AUTOSAR XML (schema 4-3-0)
package /ComponentTypes
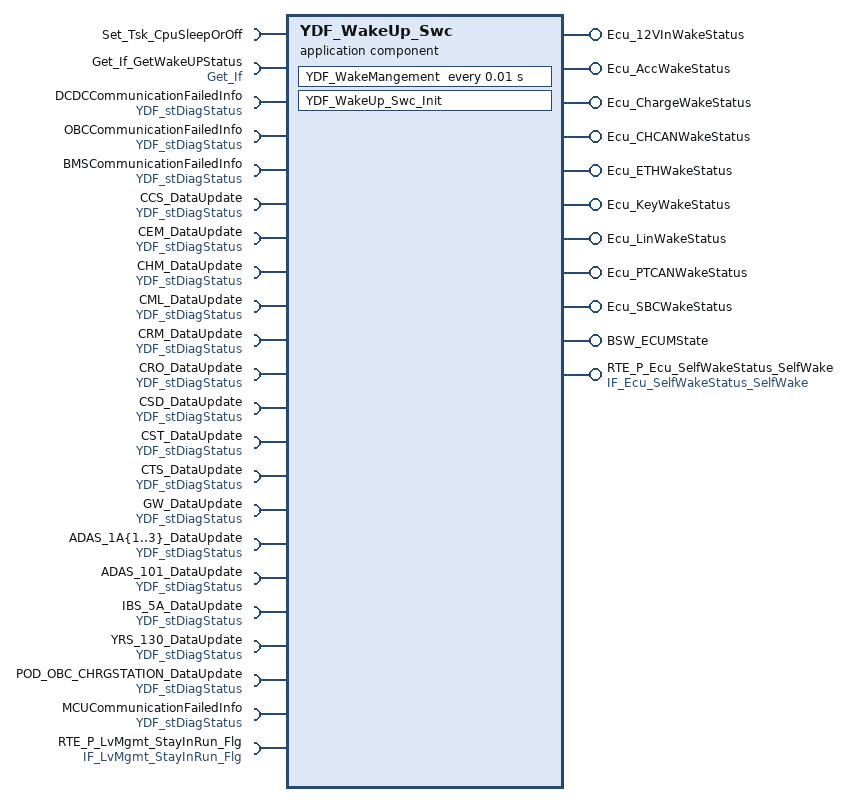
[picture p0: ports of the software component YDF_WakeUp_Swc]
  application sw component type YDF_WakeUp_Swc
    22 x require port:
      Set_Tsk_CpuSleepOrOff: client-com-spec=Set_Tsk_CpuSleepOrOff, required-interface=Set_Tsk_CpuSleepOrOff
      Get_If_GetWakeUPStatus: required-interface=Get_If
        required-com-specs:
          Get_Ad_Result
          Get_io_inResult
          Get_BTS_OutResult
          Get_CAN_ActiveInf
          Icu_17_GtmCcu6_PWMIN_CH{1..4}
          Icu_17_GtmCcu6_PWMIN_PWMSCB1
          Icu_17_GtmCcu6_PWMIN_PWMSCB2
          Icu_17_GtmCcu6_PWMIN_LAMPSCB1
          Icu_17_GtmCcu6_PWMIN_LAMPSCB2
          Get_Bottom_Ver
          Get_SentData
          Get_Level_OutResult
          Get_PwmOrLevel_OutResult
          Get_Motor_OutResult
      DCDCCommunicationFailedInfo: nonqueued-receiver-com-spec{data-element=DiagStatus, enable-update=true, filter=data-filter-type=ALWAYS, init-value=0}, required-interface=YDF_stDiagStatus
      OBCCommunicationFailedInfo: nonqueued-receiver-com-spec{data-element=DiagStatus, enable-update=true, filter=data-filter-type=ALWAYS, init-value=0}, required-interface=YDF_stDiagStatus
      BMSCommunicationFailedInfo: nonqueued-receiver-com-spec{data-element=DiagStatus, enable-update=true, filter=data-filter-type=ALWAYS, init-value=0}, required-interface=YDF_stDiagStatus
      CCS_DataUpdate: nonqueued-receiver-com-spec{data-element=DiagStatus, enable-update=true, filter=data-filter-type=ALWAYS, init-value=0}, required-interface=YDF_stDiagStatus
      CEM_DataUpdate: nonqueued-receiver-com-spec{data-element=DiagStatus, enable-update=true, filter=data-filter-type=ALWAYS, init-value=0}, required-interface=YDF_stDiagStatus
      CHM_DataUpdate: nonqueued-receiver-com-spec{data-element=DiagStatus, enable-update=true, filter=data-filter-type=ALWAYS, init-value=0}, required-interface=YDF_stDiagStatus
      CML_DataUpdate: nonqueued-receiver-com-spec{data-element=DiagStatus, enable-update=true, filter=data-filter-type=ALWAYS, init-value=0}, required-interface=YDF_stDiagStatus
      CRM_DataUpdate: nonqueued-receiver-com-spec{data-element=DiagStatus, enable-update=true, filter=data-filter-type=ALWAYS, init-value=0}, required-interface=YDF_stDiagStatus
      CRO_DataUpdate: nonqueued-receiver-com-spec{data-element=DiagStatus, enable-update=true, filter=data-filter-type=ALWAYS, init-value=0}, required-interface=YDF_stDiagStatus
      CSD_DataUpdate: nonqueued-receiver-com-spec{data-element=DiagStatus, enable-update=true, filter=data-filter-type=ALWAYS, init-value=0}, required-interface=YDF_stDiagStatus
      CST_DataUpdate: nonqueued-receiver-com-spec{data-element=DiagStatus, enable-update=true, filter=data-filter-type=ALWAYS, init-value=0}, required-interface=YDF_stDiagStatus
      CTS_DataUpdate: nonqueued-receiver-com-spec{data-element=DiagStatus, enable-update=true, filter=data-filter-type=ALWAYS, init-value=0}, required-interface=YDF_stDiagStatus
      GW_DataUpdate: nonqueued-receiver-com-spec{data-element=DiagStatus, enable-update=true, filter=data-filter-type=ALWAYS, init-value=0}, required-interface=YDF_stDiagStatus
      ADAS_1A{1..3}_DataUpdate: nonqueued-receiver-com-spec{data-element=DiagStatus, enable-update=true, filter=data-filter-type=ALWAYS, init-value=0}, required-interface=YDF_stDiagStatus
      ADAS_101_DataUpdate: nonqueued-receiver-com-spec{data-element=DiagStatus, enable-update=true, filter=data-filter-type=ALWAYS, init-value=0}, required-interface=YDF_stDiagStatus
      IBS_5A_DataUpdate: nonqueued-receiver-com-spec{data-element=DiagStatus, enable-update=true, filter=data-filter-type=ALWAYS, init-value=0}, required-interface=YDF_stDiagStatus
      YRS_130_DataUpdate: nonqueued-receiver-com-spec{data-element=DiagStatus, enable-update=true, filter=data-filter-type=ALWAYS, init-value=0}, required-interface=YDF_stDiagStatus
      POD_OBC_CHRGSTATION_DataUpdate: nonqueued-receiver-com-spec{data-element=DiagStatus, enable-update=true, filter=data-filter-type=ALWAYS, init-value=0}, required-interface=YDF_stDiagStatus
    10 x provide port:
      Ecu_12VInWakeStatus: nonqueued-sender-com-spec{data-element=st12VInwake, init-value=0}, provided-interface=Ecu_12VInWakeStatus
      Ecu_AccWakeStatus: nonqueued-sender-com-spec{data-element=Accwake, init-value=0}, provided-interface=Ecu_AccWakeStatus
      Ecu_ChargeWakeStatus: nonqueued-sender-com-spec{data-element=Chargewake, init-value=0}, provided-interface=Ecu_ChargeWakeStatus
      Ecu_CHCANWakeStatus: nonqueued-sender-com-spec{data-element=CHCANwake, init-value=0}, provided-interface=Ecu_CHCANWakeStatus
      Ecu_ETHWakeStatus: nonqueued-sender-com-spec{data-element=ETHwake, init-value=0}, provided-interface=Ecu_ETHWakeStatus
      Ecu_KeyWakeStatus: nonqueued-sender-com-spec{data-element=Keywake, init-value=0}, provided-interface=Ecu_KeyWakeStatus
      Ecu_LinWakeStatus: nonqueued-sender-com-spec=Linwake, provided-interface=Ecu_LinWakeStatus
      Ecu_PTCANWakeStatus: nonqueued-sender-com-spec{data-element=PTCANwake, init-value=0}, provided-interface=Ecu_PTCANWakeStatus
      Ecu_SBCWakeStatus: nonqueued-sender-com-spec{data-element=SBCwake, init-value=0}, provided-interface=Ecu_SBCWakeStatus
      BSW_ECUMState: nonqueued-sender-com-spec{data-element=BSWState, init-value=0}, provided-interface=BSW_ECUMState
    require port MCUCommunicationFailedInfo: nonqueued-receiver-com-spec{data-element=DiagStatus, init-value=0}, required-interface=YDF_stDiagStatus
    require port RTE_P_LvMgmt_StayInRun_Flg: nonqueued-receiver-com-spec{data-element=tec_LvMgmt_StayInRun_Flg, filter=data-filter-type=ALWAYS, init-value=0}, required-interface=IF_LvMgmt_StayInRun_Flg
    provide port RTE_P_Ecu_SelfWakeStatus_SelfWake: nonqueued-sender-com-spec{data-element=tec_Ecu_SelfWakeStatus_SelfWake, init-value=0}, provided-interface=IF_Ecu_SelfWakeStatus_SelfWake
    behavior YDF_WakeUp_Swc_InternalBehavior
      timing event TMT_YDF_WakeMangement: start-on-event=YDF_WakeMangement, period=0.01
      init event YDF_WakeUp_Swc_InitEvent: start-on-event=YDF_WakeUp_Swc_Init
      runnable YDF_WakeMangement
        data-receive-point-by-arguments:
          20 x access:
            REC_BMSCommunicationFailedInfo_DiagStatus: accessed-variable=BMSCommunicationFailedInfo.DiagStatus
            REC_DCDCCommunicationFailedInfo_DiagStatus: accessed-variable=DCDCCommunicationFailedInfo.DiagStatus
            REC_OBCCommunicationFailedInfo_DiagStatus: accessed-variable=OBCCommunicationFailedInfo.DiagStatus
            REC_CCS_DataUpdate_DiagStatus: accessed-variable=CCS_DataUpdate.DiagStatus
            REC_CEM_DataUpdate_DiagStatus: accessed-variable=CEM_DataUpdate.DiagStatus
            REC_CHM_DataUpdate_DiagStatus: accessed-variable=CHM_DataUpdate.DiagStatus
            REC_CML_DataUpdate_DiagStatus: accessed-variable=CML_DataUpdate.DiagStatus
            REC_CRM_DataUpdate_DiagStatus: accessed-variable=CRM_DataUpdate.DiagStatus
            REC_CRO_DataUpdate_DiagStatus: accessed-variable=CRO_DataUpdate.DiagStatus
            REC_CSD_DataUpdate_DiagStatus: accessed-variable=CSD_DataUpdate.DiagStatus
            REC_CST_DataUpdate_DiagStatus: accessed-variable=CST_DataUpdate.DiagStatus
            REC_CTS_DataUpdate_DiagStatus: accessed-variable=CTS_DataUpdate.DiagStatus
            REC_ADAS_101_DataUpdate_DiagStatus: accessed-variable=ADAS_101_DataUpdate.DiagStatus
            REC_ADAS_1A{1..3}_DataUpdate_DiagStatus: accessed-variable=ADAS_1A{1..3}_DataUpdate.DiagStatus
            REC_GW_DataUpdate_DiagStatus: accessed-variable=GW_DataUpdate.DiagStatus
            REC_IBS_5A_DataUpdate_DiagStatus: accessed-variable=IBS_5A_DataUpdate.DiagStatus
            REC_YRS_130_DataUpdate_DiagStatus: accessed-variable=YRS_130_DataUpdate.DiagStatus
            REC_POD_OBC_CHRGSTATION_DataUpdate_DiagStatus: accessed-variable=POD_OBC_CHRGSTATION_DataUpdate.DiagStatus
        data-send-points:
          11 x access:
            SEND_Ecu_12VInWakeStatus_st12VInwake: accessed-variable=Ecu_12VInWakeStatus.st12VInwake
            SEND_Ecu_AccWakeStatus_Accwake: accessed-variable=Ecu_AccWakeStatus.Accwake
            SEND_Ecu_CHCANWakeStatus_CHCANwake: accessed-variable=Ecu_CHCANWakeStatus.CHCANwake
            SEND_Ecu_ChargeWakeStatus_Chargewake: accessed-variable=Ecu_ChargeWakeStatus.Chargewake
            SEND_Ecu_ETHWakeStatus_ETHwake: accessed-variable=Ecu_ETHWakeStatus.ETHwake
            SEND_Ecu_KeyWakeStatus_Keywake: accessed-variable=Ecu_KeyWakeStatus.Keywake
            SEND_Ecu_LinWakeStatus_Linwake: accessed-variable=Ecu_LinWakeStatus.Linwake
            SEND_Ecu_PTCANWakeStatus_PTCANwake: accessed-variable=Ecu_PTCANWakeStatus.PTCANwake
            SEND_Ecu_SBCWakeStatus_SBCwake: accessed-variable=Ecu_SBCWakeStatus.SBCwake
            SEND_BSW_ECUMState_BSWState: accessed-variable=BSW_ECUMState.BSWState
            SEND_RTE_P_Ecu_SelfWakeStatus_SelfWake_tec_Ecu_SelfWakeStatus_SelfWake: accessed-variable=RTE_P_Ecu_SelfWakeStatus_SelfWake.tec_Ecu_SelfWakeStatus_SelfWake
        4 x sync call:
          SC_Set_Tsk_CpuSleepOrOff_Set_Tsk_CpuSleepOrOff: operation=Set_Tsk_CpuSleepOrOff.Set_Tsk_CpuSleepOrOff
          SC_Get_If_GetWakeUPStatus_Get_Ad_Result: operation=Get_If_GetWakeUPStatus.Get_Ad_Result
          SC_Get_If_GetWakeUPStatus_Get_CAN_ActiveInf: operation=Get_If_GetWakeUPStatus.Get_CAN_ActiveInf
          SC_Get_If_GetWakeUPStatus_Get_io_inResult: operation=Get_If_GetWakeUPStatus.Get_io_inResult
      runnable YDF_WakeUp_Swc_Init
  swc implementation YDF_WakeUp_Swc_Implementation: behavior=YDF_WakeUp_Swc_InternalBehavior
